# STM32WB55x register map
File version: 1.0
CPU: CM4 r0p1, little endian, 4 interrupt priority bits
Registers are 32-bit, read-write, reset 0x0 unless marked. A register's access mark holds for its fields unless they carry their own. Offsets are from the block's base; [hi:lo] are bit positions; {n}, {i} and the like mark numbered series; 'fields as' and 'values as' point back to an identical list.

## CRC
Base 0x40023000
0x00 DR
0x04 IDR
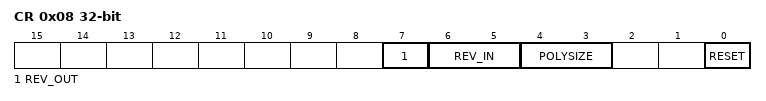
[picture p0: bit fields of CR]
0x08 CR
  [7] REV_OUT, [6:5] REV_IN, [4:3] POLYSIZE, [0] RESET
0x10 INIT
  [31:0] CRC_INIT
0x14 POL
  [31:0] POLY

## DMAMUX
Base 0x40020800
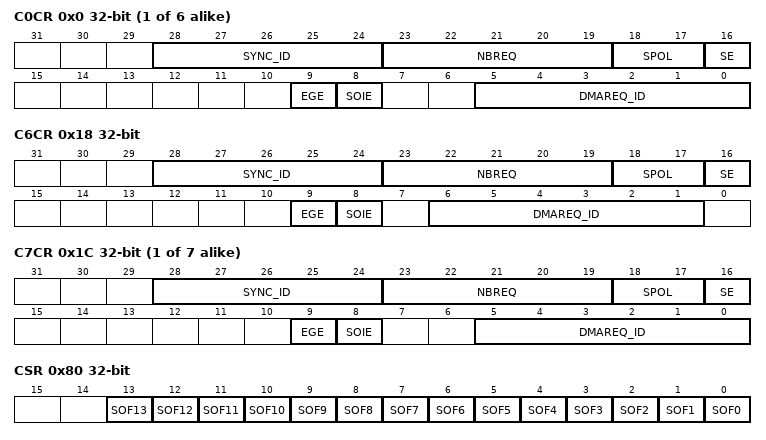
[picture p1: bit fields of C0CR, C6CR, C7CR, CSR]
{0x0+4i} C{i}CR (i=0..5)
  [28:24] SYNC_ID, [23:19] NBREQ, [18:17] SPOL, [16] SE, [9] EGE, [8] SOIE, [5:0] DMAREQ_ID
0x18 C6CR
  [28:24] SYNC_ID, [23:19] NBREQ, [18:17] SPOL, [16] SE, [9] EGE, [8] SOIE, [6:1] DMAREQ_ID
{0x0+4i} C{i}CR (i=7..13)
  fields as C0CR
0x80 CSR
  [n] SOF{n} (n=0..13)
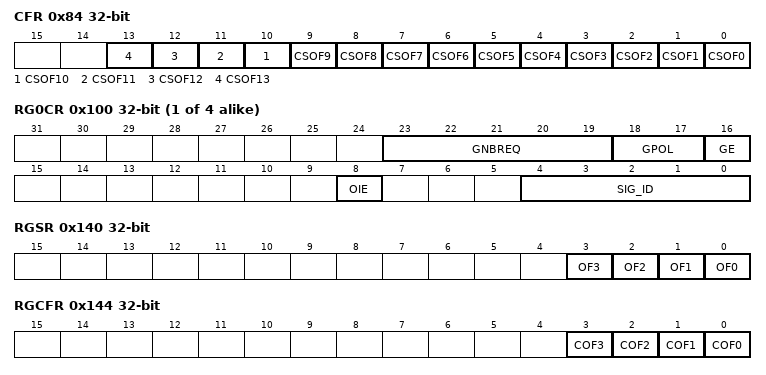
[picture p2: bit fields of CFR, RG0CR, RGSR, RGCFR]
0x84 CFR
  [n] CSOF{n} (n=0..13)
{0x100+4i} RG{i}CR (i=0..3)
  [23:19] GNBREQ, [18:17] GPOL, [16] GE, [8] OIE, [4:0] SIG_ID
0x140 RGSR
  [n] OF{n} (n=0..3)
0x144 RGCFR
  [n] COF{n} (n=0..3)

## EXTI
Base 0x58000800
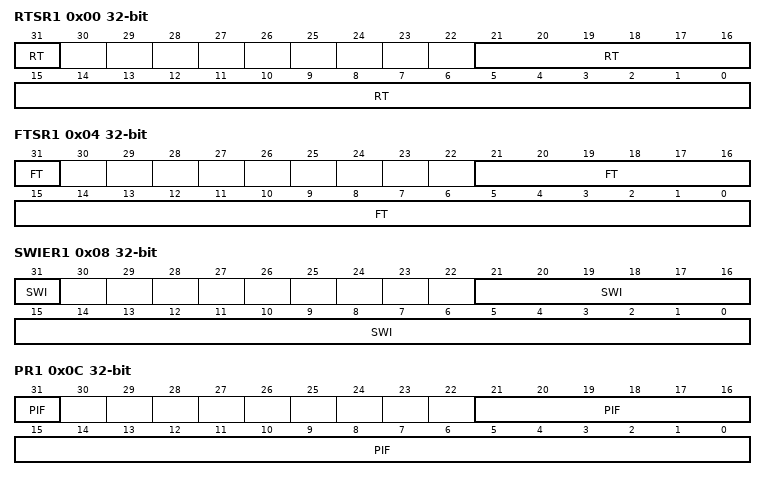
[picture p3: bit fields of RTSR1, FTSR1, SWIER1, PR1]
0x00 RTSR1
  [31] RT, [21:0] RT
0x04 FTSR1
  [31] FT, [21:0] FT
0x08 SWIER1
  [31] SWI, [21:0] SWI
0x0C PR1
  [31] PIF, [21:0] PIF
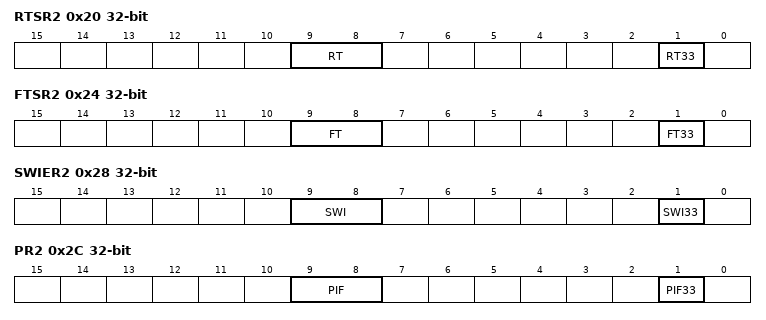
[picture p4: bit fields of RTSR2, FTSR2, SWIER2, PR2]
0x20 RTSR2
  [9:8] RT, [1] RT33
0x24 FTSR2
  [9:8] FT, [1] FT33
0x28 SWIER2
  [9:8] SWI, [1] SWI33
0x2C PR2
  [9:8] PIF, [1] PIF33
0x80 IMR1
  [31:0] IM
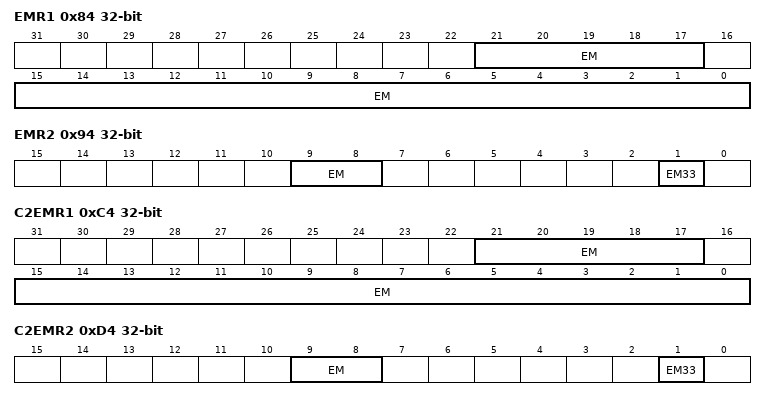
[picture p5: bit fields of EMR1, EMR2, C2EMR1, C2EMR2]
0x84 EMR1
  [21:17] EM, [15:0] EM
0x90 IMR2
  [16:0] IM
0x94 EMR2
  [9:8] EM, [1] EM33
0xC0 C2IMR1
  [31:0] IM
0xC4 C2EMR1
  [21:17] EM, [15:0] EM
0xD0 C2IMR2
  [16:0] IM
0xD4 C2EMR2
  [9:8] EM, [1] EM33

## FLASH
Base 0x58004000
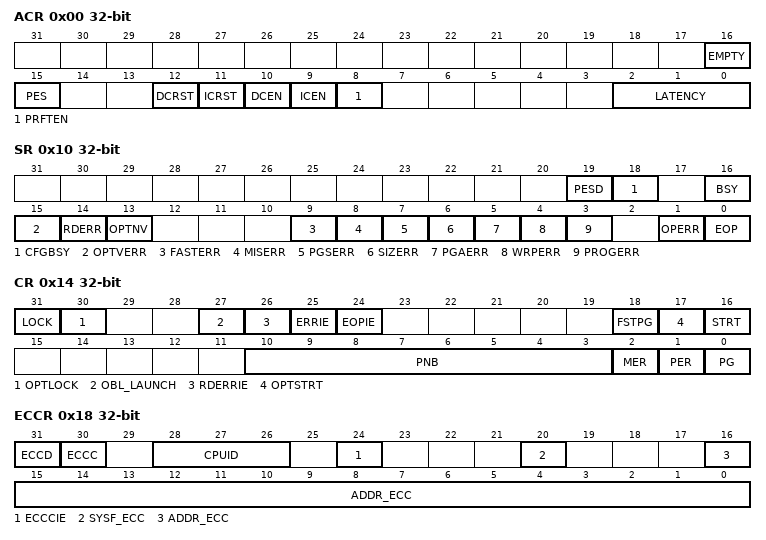
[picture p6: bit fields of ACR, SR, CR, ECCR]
0x00 ACR
  [16] EMPTY, [15] PES, [12] DCRST, [11] ICRST, [10] DCEN, [9] ICEN, [8] PRFTEN, [2:0] LATENCY
0x08 KEYR
0x0C OPTKEYR
0x10 SR
  [19] PESD, [18] CFGBSY, [16] BSY, [15] OPTVERR, [14] RDERR, [13] OPTNV, [9] FASTERR, [8] MISERR, [7] PGSERR, [6] SIZERR, [5] PGAERR, [4] WRPERR, [3] PROGERR, [1] OPERR, [0] EOP
0x14 CR
  [31] LOCK, [30] OPTLOCK, [27] OBL_LAUNCH, [26] RDERRIE, [25] ERRIE, [24] EOPIE, [18] FSTPG, [17] OPTSTRT, [16] STRT, [10:3] PNB, [2] MER, [1] PER, [0] PG
0x18 ECCR
  [31] ECCD, [30] ECCC, [28:26] CPUID, [24] ECCCIE, [20] SYSF_ECC, [16:0] ADDR_ECC
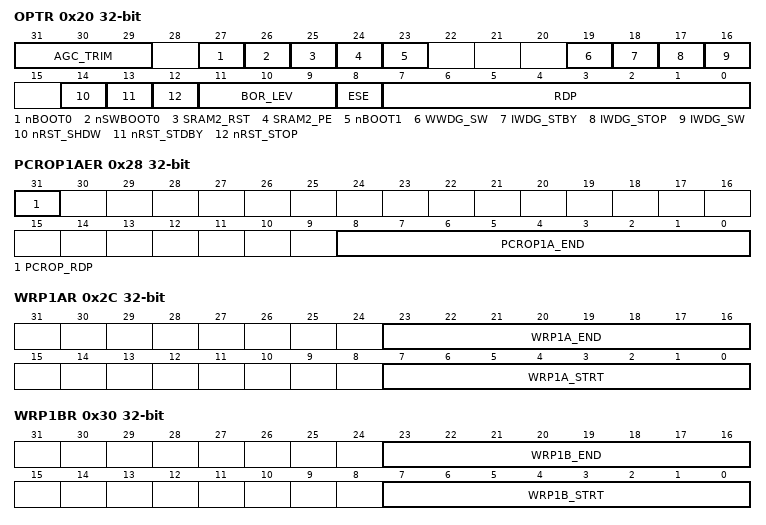
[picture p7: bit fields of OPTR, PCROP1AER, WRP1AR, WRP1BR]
0x20 OPTR
  [31:29] AGC_TRIM, [27] nBOOT0, [26] nSWBOOT0, [25] SRAM2_RST, [24] SRAM2_PE, [23] nBOOT1, [19] WWDG_SW, [18] IWDG_STBY, [17] IWDG_STOP, [16] IWDG_SW, [14] nRST_SHDW, [13] nRST_STDBY, [12] nRST_STOP, [11:9] BOR_LEV, [8] ESE, [7:0] RDP
0x24 PCROP1ASR
  [8:0] PCROP1A_STRT
0x28 PCROP1AER
  [31] PCROP_RDP, [8:0] PCROP1A_END
0x2C WRP1AR
  [23:16] WRP1A_END, [7:0] WRP1A_STRT
0x30 WRP1BR
  [23:16] WRP1B_END, [7:0] WRP1B_STRT
0x34 PCROP1BSR
  [8:0] PCROP1B_STRT
0x38 PCROP1BER
  [8:0] PCROP1B_END
0x3C IPCCBR
  [13:0] IPCCDBA
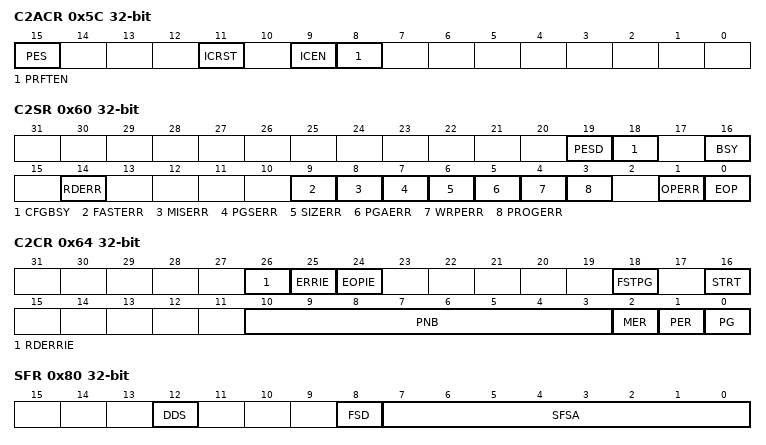
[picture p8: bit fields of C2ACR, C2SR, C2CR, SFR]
0x5C C2ACR
  [15] PES, [11] ICRST, [9] ICEN, [8] PRFTEN
0x60 C2SR
  [19] PESD, [18] CFGBSY, [16] BSY, [14] RDERR, [9] FASTERR, [8] MISERR, [7] PGSERR, [6] SIZERR, [5] PGAERR, [4] WRPERR, [3] PROGERR, [1] OPERR, [0] EOP
0x64 C2CR
  [26] RDERRIE, [25] ERRIE, [24] EOPIE, [18] FSTPG, [16] STRT, [10:3] PNB, [2] MER, [1] PER, [0] PG
0x80 SFR
  [12] DDS, [8] FSD, [7:0] SFSA
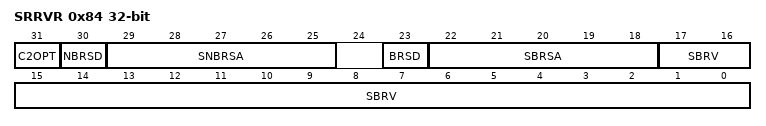
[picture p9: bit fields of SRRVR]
0x84 SRRVR
  [31] C2OPT, [30] NBRSD, [29:25] SNBRSA, [23] BRSD, [22:18] SBRSA, [17:0] SBRV

## PKA
Base 0x58002000
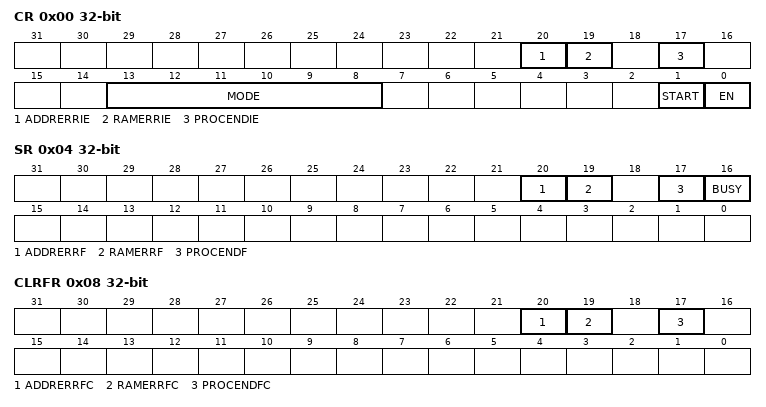
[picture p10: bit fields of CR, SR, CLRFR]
0x00 CR
  [20] ADDRERRIE, [19] RAMERRIE, [17] PROCENDIE, [13:8] MODE, [1] START, [0] EN
0x04 SR
  [20] ADDRERRF, [19] RAMERRF, [17] PROCENDF, [16] BUSY
0x08 CLRFR
  [20] ADDRERRFC, [19] RAMERRFC, [17] PROCENDFC

## HSEM
Base 0x58001400
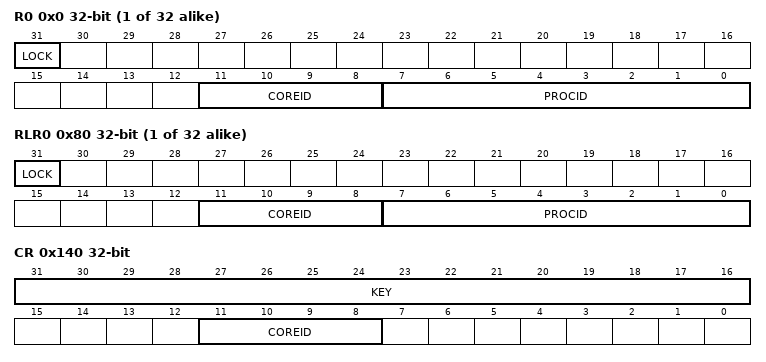
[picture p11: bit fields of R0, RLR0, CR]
{0x0+4i} R{i} (i=0..31)
  [31] LOCK, [11:8] COREID, [7:0] PROCID
{0x80+4i} RLR{i} (i=0..31)
  [31] LOCK, [11:8] COREID, [7:0] PROCID
0x100 C1IER
  [31:0] ISE
0x104 C1ICR
  [31:0] ISC
0x108 C1ISR
  [31:0] ISF
0x10C C1MISR
  [31:0] MISF
0x110 C2IER
  [31:0] ISE
0x114 C2ICR
  [31:0] ISC
0x118 C2ISR
  [31:0] ISF
0x11C C2MISR
  [31:0] MISF
0x140 CR
  [31:16] KEY, [11:8] COREID
0x144 KEYR
  [31:16] KEY

## PWR
Base 0x58000400
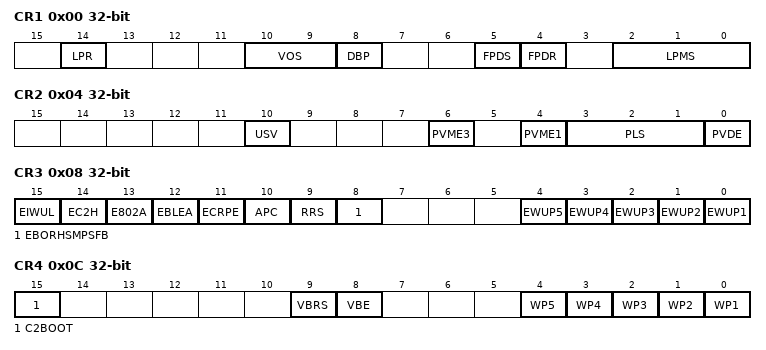
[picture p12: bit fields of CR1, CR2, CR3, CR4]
0x00 CR1
  [14] LPR, [10:9] VOS, [8] DBP, [5] FPDS, [4] FPDR, [2:0] LPMS
0x04 CR2
  [10] USV, [6] PVME3, [4] PVME1, [3:1] PLS, [0] PVDE
0x08 CR3
  [15] EIWUL, [14] EC2H, [13] E802A, [12] EBLEA, [11] ECRPE, [10] APC, [9] RRS, [8] EBORHSMPSFB, [n-1] EWUP{n} (n=1..5)
0x0C CR4
  [15] C2BOOT, [9] VBRS, [8] VBE, [n-1] WP{n} (n=1..5)
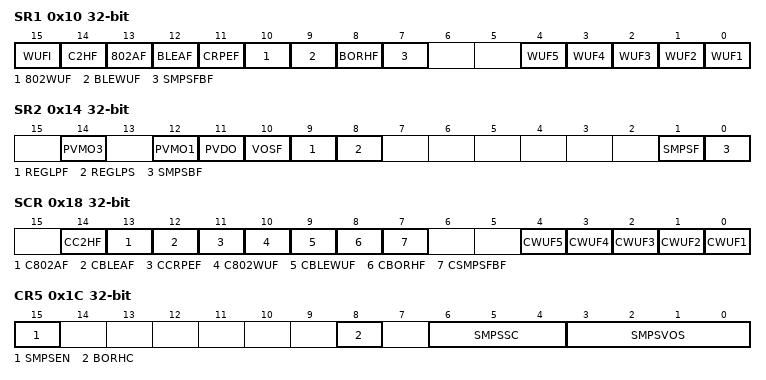
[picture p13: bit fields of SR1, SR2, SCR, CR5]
0x10 SR1
  [15] WUFI, [14] C2HF, [13] 802AF, [12] BLEAF, [11] CRPEF, [10] 802WUF, [9] BLEWUF, [8] BORHF, [7] SMPSFBF, [n-1] WUF{n} (n=1..5)
0x14 SR2
  [14] PVMO3, [12] PVMO1, [11] PVDO, [10] VOSF, [9] REGLPF, [8] REGLPS, [1] SMPSF, [0] SMPSBF
0x18 SCR
  [14] CC2HF, [13] C802AF, [12] CBLEAF, [11] CCRPEF, [10] C802WUF, [9] CBLEWUF, [8] CBORHF, [7] CSMPSFBF, [n-1] CWUF{n} (n=1..5)
0x1C CR5
  [15] SMPSEN, [8] BORHC, [6:4] SMPSSC, [3:0] SMPSVOS
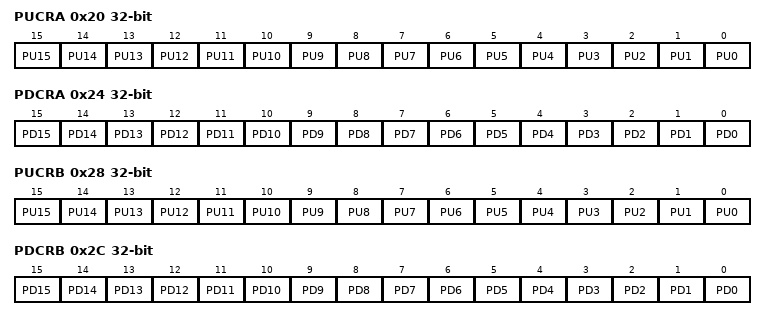
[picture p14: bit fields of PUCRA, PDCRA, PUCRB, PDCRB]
0x20 PUCRA
  [n] PU{n} (n=0..15)
0x24 PDCRA
  [n] PD{n} (n=0..15)
0x28 PUCRB
  [n] PU{n} (n=0..15)
0x2C PDCRB
  [n] PD{n} (n=0..15)
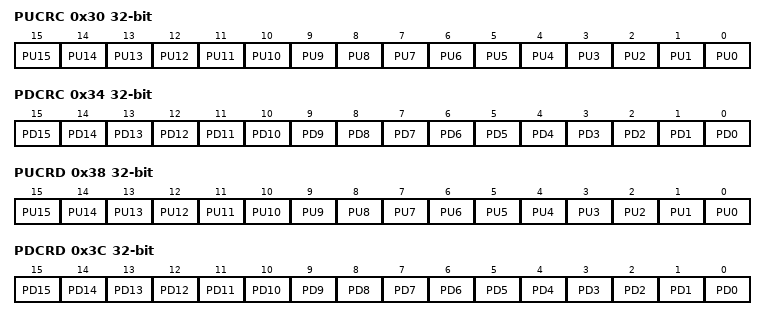
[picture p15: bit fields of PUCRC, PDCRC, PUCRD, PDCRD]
0x30 PUCRC
  [n] PU{n} (n=0..15)
0x34 PDCRC
  [n] PD{n} (n=0..15)
0x38 PUCRD
  [n] PU{n} (n=0..15)
0x3C PDCRD
  [n] PD{n} (n=0..15)
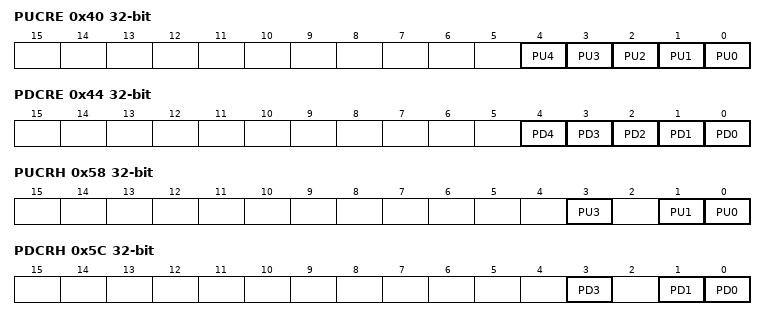
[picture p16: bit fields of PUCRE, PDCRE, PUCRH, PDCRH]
0x40 PUCRE
  [n] PU{n} (n=0..4)
0x44 PDCRE
  [n] PD{n} (n=0..4)
0x58 PUCRH
  [3] PU3, [1] PU1, [0] PU0
0x5C PDCRH
  [3] PD3, [1] PD1, [0] PD0
0x80 C2CR1
  [15] 802EWKUP, [14] BLEEWKUP, [5] FPDS, [4] FPDR, [2:0] LPMS
0x84 C2CR3
  [15] EIWUL, [12] APC, [10] E802IWUP, [9] EBLEWUP, [n-1] EWUP{n} (n=1..5)
0x88 EXTSCR
  [15] C2DS, [14] C1DS, [13] CRPF, [11] C2STOPF, [10] C2SBF, [9] C1STOPF, [8] C1SBF, [2] CCRPF, [1] C2CSSF, [0] C1CSSF
